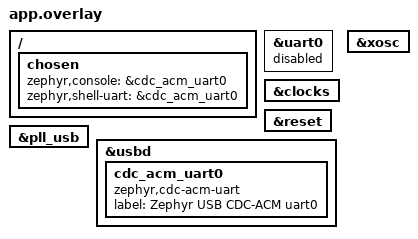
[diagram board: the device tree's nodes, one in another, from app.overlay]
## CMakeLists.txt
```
cmake_minimum_required(VERSION 3.20.0)

find_package(Zephyr REQUIRED HINTS $ENV{ZEPHYR_BASE})
project(w6300_driver_test)

# Add missing Pico SDK include paths
zephyr_include_directories(
    ${ZEPHYR_HAL_RPI_PICO_MODULE_DIR}/src/rp2_common/hardware_gpio/include
    ${ZEPHYR_HAL_RPI_PICO_MODULE_DIR}/src/rp2_common/hardware_base/include
    ${ZEPHYR_HAL_RPI_PICO_MODULE_DIR}/src/common/pico_base_headers/include
)

# Include main source and driver source
target_sources(app PRIVATE 
    src/main.c
    drivers/ethernet/eth_w6300.c
)

# Add driver directory to include path
target_include_directories(app PRIVATE drivers/ethernet)
```

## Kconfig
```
mainmenu "W6300 Driver Test"

rsource "drivers/ethernet/Kconfig"

rsource "boards/wiznet/rp2350_w6300_evb/Kconfig.board"

source "Kconfig.zephyr"
```

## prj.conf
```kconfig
# Core USB Device Stack (Legacy Stack)
CONFIG_USB_DEVICE_STACK=y
CONFIG_USB_DEVICE_INITIALIZE_AT_BOOT=y
CONFIG_USB_DC_RPI_PICO=y

# USB CDC ACM Class Configuration
CONFIG_USB_CDC_ACM=y
CONFIG_UART_LINE_CTRL=y
CONFIG_USB_DEVICE_PRODUCT="Zephyr USB CDC Console"
CONFIG_USB_DEVICE_VID=0x2E8A
CONFIG_USB_DEVICE_PID=0x0005

# Serial, Console, and Logging for CDC ACM
CONFIG_SERIAL=y
CONFIG_CONSOLE=y
CONFIG_UART_CONSOLE=y
CONFIG_UART_LINE_CTRL=y
CONFIG_UART_INTERRUPT_DRIVEN=y

# Logging
CONFIG_LOG=y
CONFIG_LOG_DEFAULT_LEVEL=3
CONFIG_PRINTK=y
CONFIG_LOG_MODE_IMMEDIATE=y

# RPi Pico drivers
CONFIG_CLOCK_CONTROL=y
CONFIG_CLOCK_CONTROL_RPI_PICO=y
CONFIG_RESET=y
CONFIG_RESET_RPI_PICO=y

# Build Output
CONFIG_BUILD_OUTPUT_UF2=y

# --- Networking Engine (Testing Stage 3: Priority) ---
CONFIG_NETWORKING=y
CONFIG_NET_NATIVE=y
CONFIG_NET_L2_ETHERNET=y
CONFIG_NET_IPV4=y
CONFIG_NET_TCP=y
CONFIG_NET_SOCKETS=y
# CONFIG_NET_SOCKETS_POSIX_NAMES=y
CONFIG_ENTROPY_GENERATOR=y
CONFIG_TEST_RANDOM_GENERATOR=y
# CONFIG_NET_INIT_PRIORITY=99

# Minimal Buffers to Save Memory
CONFIG_NET_PKT_RX_COUNT=2
CONFIG_NET_PKT_TX_COUNT=2
CONFIG_NET_BUF_RX_COUNT=4
CONFIG_NET_BUF_TX_COUNT=4
CONFIG_MAIN_STACK_SIZE=4096
CONFIG_HEAP_MEM_POOL_SIZE=8192

# Hardware Support (Keep Disabled for now)
CONFIG_GPIO=y
# CONFIG_SPI=y
# CONFIG_SPI_BITBANG=y
CONFIG_ETH_W6300=y

# Minimal Buffers to Save Memory
```

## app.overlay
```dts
/ {
	chosen {
		zephyr,console = &cdc_acm_uart0;
		zephyr,shell-uart = &cdc_acm_uart0;
	};
};

&uart0 {
	status = "disabled";
};

&clocks {
	status = "okay";
};

&reset {
	status = "okay";
};

&xosc {
	status = "okay";
};

&pll_usb {
	status = "okay";
};

&usbd {
	status = "okay";
	cdc_acm_uart0: cdc_acm_uart0 {
		compatible = "zephyr,cdc-acm-uart";
		label = "Zephyr USB CDC-ACM uart0";
	};
};
```

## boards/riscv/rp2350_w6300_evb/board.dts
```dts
/dts-v1/;

/* 
 * NOTE: We assume generic RP2350 support is available. 
 * You might need to adjust the include if the RP2350 dtsi is named differently.
 */
#include <rpi_pico/rp2350.dtsi> 

/ {
	model = "Raspberry Pi RP2350 W6300 EVB";
	compatible = "raspberrypi,rp2350-w6300-evb";

	chosen {
		zephyr,sram = &sram0;
		zephyr,flash = &flash0;
		zephyr,console = &uart0;
		zephyr,shell-uart = &uart0;
	};
};

&uart0 {
	status = "okay";
	current-speed = <115200>;
};

/* Using software SPI (Bitbang) because pins do not match standard HW SPI0 */
spi_w6300: spi-bitbang {
	compatible = "zephyr,spi-bitbang";
	status = "okay";
	#address-cells = <1>;
	#size-cells = <0>;
	clk-gpios = <&gpio0 17 GPIO_ACTIVE_HIGH>;
	mosi-gpios = <&gpio0 18 GPIO_ACTIVE_HIGH>;
	miso-gpios = <&gpio0 19 GPIO_ACTIVE_HIGH>;
	cs-gpios = <&gpio0 16 GPIO_ACTIVE_LOW>;

	w6300: w6300@0 {
		compatible = "wiznet,w6300";
		reg = <0>;
		spi-max-frequency = <10000000>;
		int-gpios = <&gpio0 15 GPIO_ACTIVE_LOW>;
	};
};
```

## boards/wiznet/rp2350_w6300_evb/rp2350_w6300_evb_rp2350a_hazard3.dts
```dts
/dts-v1/;

#include <raspberrypi/rpi_pico/rp2350a.dtsi>
#include <riscv/raspberrypi/hazard3.dtsi>

/ {
	model = "Raspberry Pi RP2350 W6300 EVB";
	compatible = "raspberrypi,rp2350-w6300-evb";

	chosen {
		zephyr,sram = &sram0;
		zephyr,flash = &flash0;
		zephyr,console = &uart0;
		zephyr,shell-uart = &uart0;
	};
};

&xosc {
	clock-frequency = <12000000>;
	status = "okay";
};

&gpio0 {
	status = "okay";
};

&flash0 {
	reg = <0x10000000 0x200000>;
};

&uart0 {
	status = "okay";
	current-speed = <115200>;
};

/ {

/* Using software SPI (Bitbang) because pins do not match standard HW SPI0 */

spi_w6300: spi-bitbang {

	compatible = "zephyr,spi-bitbang";

	status = "disabled";

	#address-cells = <1>;

	#size-cells = <0>;

	clk-gpios = <&gpio0 17 GPIO_ACTIVE_HIGH>;


        mosi-gpios = <&gpio0 18 GPIO_ACTIVE_HIGH>;
        miso-gpios = <&gpio0 19 GPIO_ACTIVE_HIGH>;
        cs-gpios = <&gpio0 16 GPIO_ACTIVE_LOW>;

        w6300: w6300@0 {
                compatible = "wiznet,w6300";
                reg = <0>;
                spi-max-frequency = <500000>;
                int-gpios = <&gpio0 15 GPIO_ACTIVE_LOW>;
                reset-gpios = <&gpio0 22 GPIO_ACTIVE_LOW>;
                io2-gpios = <&gpio0 20 GPIO_ACTIVE_HIGH>;
                io3-gpios = <&gpio0 21 GPIO_ACTIVE_HIGH>;
        };
};
};
```

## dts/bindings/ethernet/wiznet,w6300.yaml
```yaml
description: Wiznet W6300 Ethernet Controller

compatible: "wiznet,w6300"

include: spi-device.yaml

properties:
  int-gpios:
    type: phandle-array
    required: true
    description: Interrupt GPIO pin

  reset-gpios:
    type: phandle-array
    required: false
    description: Reset GPIO pin

  io2-gpios:
    type: phandle-array
    required: false
    description: Extra IO2 GPIO pin

  io3-gpios:
    type: phandle-array
    required: false
    description: Extra IO3 GPIO pin
```

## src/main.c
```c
#include <zephyr/kernel.h>
#include <zephyr/logging/log.h>
#include <zephyr/usb/usb_device.h>
#include <zephyr/drivers/uart.h>
#include <zephyr/net/net_if.h>
#include <zephyr/net/net_core.h>
#include <zephyr/net/net_ip.h>
#include <zephyr/net/socket.h>
#include <errno.h>

LOG_MODULE_REGISTER(main);

#define HTTP_PORT 8080

static const char http_response[] =
	"HTTP/1.1 200 OK\r\n"
	"Content-Type: text/html\r\n"
	"Connection: close\r\n"
	"\r\n"
	"<!DOCTYPE html><html><head><title>Pico2 W6300 Server</title></head>"
	"<body><h1>Hello, MZSZ!</h1>"
	"<p>This page is served by Zephyr RTOS and WIZnet W6300 Ethernet.</p>"
	"</body></html>";

void start_http_server(void)
{
	int serv;
	struct sockaddr_in bind_addr;
	struct net_if *iface;

	LOG_INF("Waiting for network interface...");
	iface = net_if_get_default();
	while (iface == NULL) {
		k_sleep(K_MSEC(100));
		iface = net_if_get_default();
	}

	while (!net_if_is_up(iface)) {
		k_sleep(K_MSEC(200));
	}

	while (net_if_ipv4_get_global_addr(iface, NET_ADDR_PREFERRED) == NULL) {
		k_sleep(K_MSEC(200));
	}

	LOG_INF("Network interface is up with IPv4 address assigned.");

	serv = zsock_socket(AF_INET, SOCK_STREAM, IPPROTO_TCP);
	bind_addr.sin_family = AF_INET;
	bind_addr.sin_port = htons(HTTP_PORT);
	bind_addr.sin_addr.s_addr = INADDR_ANY;

	if (serv < 0) {
		LOG_ERR("Failed to create socket: %d", errno);
		return;
	}

	if (zsock_bind(serv, (struct sockaddr *)&bind_addr, sizeof(bind_addr)) < 0) {
		LOG_ERR("Failed to bind socket: %d", errno);
		zsock_close(serv);
		return;
	}

	if (zsock_listen(serv, 5) < 0) {
		LOG_ERR("Failed to listen on socket: %d", errno);
		zsock_close(serv);
		return;
	}

	LOG_INF("HTTP Server listening on port %d...", HTTP_PORT);

	while (1) {
		struct sockaddr_in client_addr;
		socklen_t client_addr_len = sizeof(client_addr);
		int client = zsock_accept(serv, (struct sockaddr *)&client_addr, &client_addr_len);

		if (client < 0) {
			LOG_ERR("Failed to accept connection: %d", errno);
			continue;
		}

		LOG_INF("Connection accepted");
		char buf[256];
		zsock_recv(client, buf, sizeof(buf), 0);
		zsock_send(client, http_response, sizeof(http_response) - 1, 0);
		zsock_close(client);
	}
}

K_THREAD_DEFINE(http_server_thread, 2048, start_http_server, NULL, NULL, NULL, 7, 0, 0);

int main(void)
{
	const struct device *const dev = DEVICE_DT_GET_ANY(zephyr_cdc_acm_uart);
	uint32_t dtr = 0;
	int64_t wait_start;

#if !IS_ENABLED(CONFIG_USB_DEVICE_INITIALIZE_AT_BOOT)
	int ret = usb_device_init();
	if (ret && ret != -EALREADY) {
		LOG_ERR("USB init failed: %d", ret);
	}

	ret = usb_device_enable(NULL);
	if (ret && ret != -EALREADY) {
		LOG_ERR("USB enable failed: %d", ret);
	}
#endif

	/* Wait for serial terminal connection */
	wait_start = k_uptime_get();
	while (!dtr && k_uptime_get() < (wait_start + 5000)) {
		uart_line_ctrl_get(dev, UART_LINE_CTRL_DTR, &dtr);
		k_sleep(K_MSEC(100));
	}
	if (!dtr) {
		LOG_WRN("USB serial not connected, continuing without DTR.");
	}

	LOG_INF("Hello from W6300 Driver Test App! For Risc-V");
	LOG_INF("Static IP: 192.168.0.200 (Check your router subnet!)");
	LOG_INF("W6300 Ethernet HTTP Server starting...");

	while (1)
	{
		k_sleep(K_SECONDS(10));
	}
	return 0;
}
```
